# CC13x0 register map
File version: 2.0
CPU: CM3 r2p1, little endian, no MPU, no FPU, 0x3 interrupt priority bits, 0x0 interrupts
Registers are 32-bit, read-write, reset 0x0 unless marked. A register's access mark holds for its fields unless they carry their own. Offsets are from the block's base; [hi:lo] are bit positions; {n}, {i} and the like mark numbered series.

## CCFG — Customer configuration area (CCFG)
Base 0x50003000
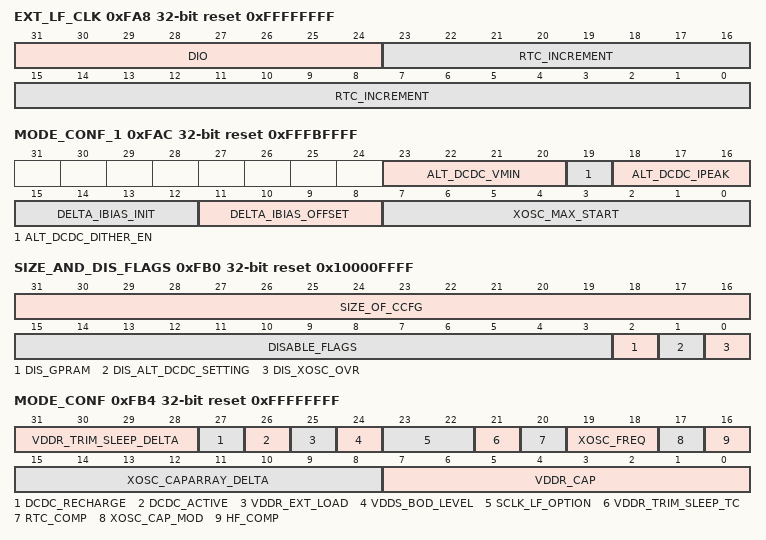
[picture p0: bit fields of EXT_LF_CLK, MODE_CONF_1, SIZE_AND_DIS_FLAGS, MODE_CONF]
0xFA8 EXT_LF_CLK ro reset 0xFFFFFFFF — Extern LF clock configuration
  [31:24] DIO, [23:0] RTC_INCREMENT
0xFAC MODE_CONF_1 ro reset 0xFFFBFFFF — Mode Configuration 1
  [23:20] ALT_DCDC_VMIN, [19] ALT_DCDC_DITHER_EN, [18:16] ALT_DCDC_IPEAK, [15:12] DELTA_IBIAS_INIT, [11:8] DELTA_IBIAS_OFFSET, [7:0] XOSC_MAX_START
0xFB0 SIZE_AND_DIS_FLAGS ro reset 0x10000FFFF — CCFG Size and Disable Flags
  [31:16] SIZE_OF_CCFG, [15:3] DISABLE_FLAGS, [2] DIS_GPRAM, [1] DIS_ALT_DCDC_SETTING, [0] DIS_XOSC_OVR
0xFB4 MODE_CONF ro reset 0xFFFFFFFF — Mode Configuration 0
  [31:28] VDDR_TRIM_SLEEP_DELTA, [27] DCDC_RECHARGE, [26] DCDC_ACTIVE, [25] VDDR_EXT_LOAD, [24] VDDS_BOD_LEVEL, [23:22] SCLK_LF_OPTION, [21] VDDR_TRIM_SLEEP_TC, [20] RTC_COMP, [19:18] XOSC_FREQ, [17] XOSC_CAP_MOD, [16] HF_COMP, [15:8] XOSC_CAPARRAY_DELTA, [7:0] VDDR_CAP
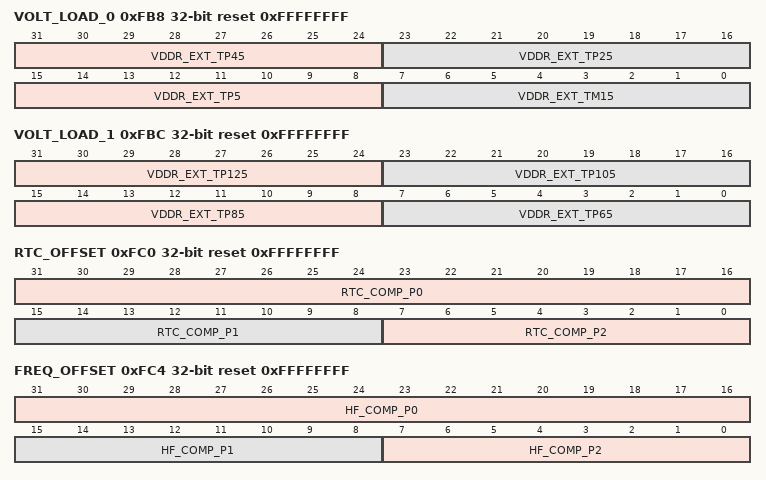
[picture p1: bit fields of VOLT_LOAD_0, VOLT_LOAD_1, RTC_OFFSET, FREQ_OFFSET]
0xFB8 VOLT_LOAD_0 ro reset 0xFFFFFFFF — Voltage Load 0 Enabled by MODE_CONF.VDDR_EXT_LOAD.
  [31:24] VDDR_EXT_TP45, [23:16] VDDR_EXT_TP25, [15:8] VDDR_EXT_TP5, [7:0] VDDR_EXT_TM15
0xFBC VOLT_LOAD_1 ro reset 0xFFFFFFFF — Voltage Load 1 Enabled by MODE_CONF.VDDR_EXT_LOAD.
  [31:24] VDDR_EXT_TP125, [23:16] VDDR_EXT_TP105, [15:8] VDDR_EXT_TP85, [7:0] VDDR_EXT_TP65
0xFC0 RTC_OFFSET ro reset 0xFFFFFFFF — Real Time Clock Offset Enabled by MODE_CONF.RTC_COMP.
  [31:16] RTC_COMP_P0, [15:8] RTC_COMP_P1, [7:0] RTC_COMP_P2
0xFC4 FREQ_OFFSET ro reset 0xFFFFFFFF — Frequency Offset
  [31:16] HF_COMP_P0, [15:8] HF_COMP_P1, [7:0] HF_COMP_P2
0xFC8 IEEE_MAC_0 ro reset 0xFFFFFFFF — IEEE MAC Address 0
  [31:0] ADDR
0xFCC IEEE_MAC_1 ro reset 0xFFFFFFFF — IEEE MAC Address 1
  [31:0] ADDR
0xFD0 IEEE_BLE_0 ro reset 0xFFFFFFFF — IEEE BLE Address 0
  [31:0] ADDR
0xFD4 IEEE_BLE_1 ro reset 0xFFFFFFFF — IEEE BLE Address 1
  [31:0] ADDR
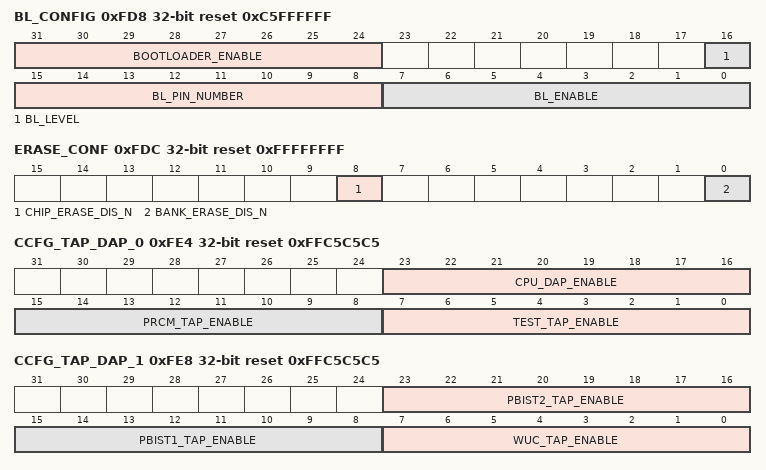
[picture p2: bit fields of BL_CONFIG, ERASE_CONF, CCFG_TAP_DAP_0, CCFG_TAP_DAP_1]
0xFD8 BL_CONFIG ro reset 0xC5FFFFFF — Bootloader Configuration Configures the functionality of the ROM boot loader. If both the boot loader is enabled by the BOOTLOADER_ENABLE field and the boot loader backdoor is enabled by the BL_ENABLE field it is possible to force entry of the ROM boot loader even if a valid image is present in flash.
  [31:24] BOOTLOADER_ENABLE, [16] BL_LEVEL, [15:8] BL_PIN_NUMBER, [7:0] BL_ENABLE
0xFDC ERASE_CONF ro reset 0xFFFFFFFF — Erase Configuration
  [8] CHIP_ERASE_DIS_N, [0] BANK_ERASE_DIS_N
0xFE0 CCFG_TI_OPTIONS ro reset 0xFFFFFFC5 — TI Options
  [7:0] TI_FA_ENABLE
0xFE4 CCFG_TAP_DAP_0 ro reset 0xFFC5C5C5 — Test Access Points Enable 0
  [23:16] CPU_DAP_ENABLE, [15:8] PRCM_TAP_ENABLE, [7:0] TEST_TAP_ENABLE
0xFE8 CCFG_TAP_DAP_1 ro reset 0xFFC5C5C5 — Test Access Points Enable 1
  [23:16] PBIST2_TAP_ENABLE, [15:8] PBIST1_TAP_ENABLE, [7:0] WUC_TAP_ENABLE
0xFEC IMAGE_VALID_CONF ro reset 0xFFFFFFFF — Image Valid
  [31:0] IMAGE_VALID
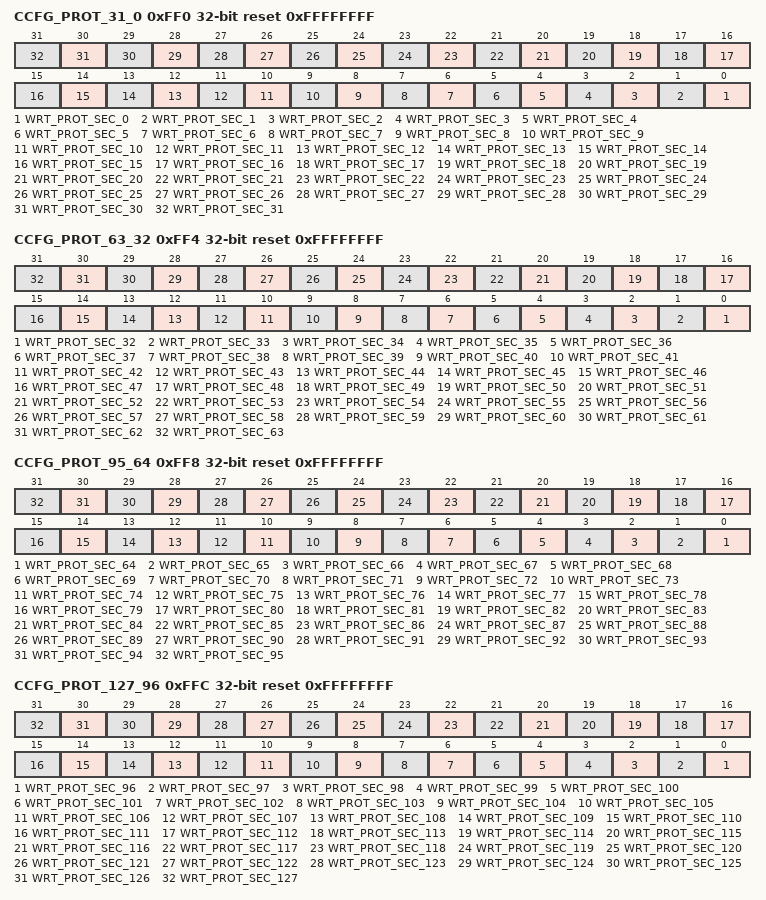
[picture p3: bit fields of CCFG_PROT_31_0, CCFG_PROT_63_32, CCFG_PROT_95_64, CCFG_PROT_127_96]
0xFF0 CCFG_PROT_31_0 ro reset 0xFFFFFFFF — Protect Sectors 0-31 Each bit write protects one 4KB flash sector from being both programmed and erased. Bit must be set to 0 in order to enable sector write protect.
  [n] WRT_PROT_SEC_{n} (n=0..31)
0xFF4 CCFG_PROT_63_32 ro reset 0xFFFFFFFF — Protect Sectors 32-63 Each bit write protects one 4KB flash sector from being both programmed and erased. Bit must be set to 0 in order to enable sector write protect. Not in use by CC26xx and CC13xx.
  [n-32] WRT_PROT_SEC_{n} (n=32..63)
0xFF8 CCFG_PROT_95_64 ro reset 0xFFFFFFFF — Protect Sectors 64-95 Each bit write protects one flash sector from being both programmed and erased. Bit must be set to 0 in order to enable sector write protect. Not in use by CC26xx and CC13xx.
  [n-64] WRT_PROT_SEC_{n} (n=64..95)
0xFFC CCFG_PROT_127_96 ro reset 0xFFFFFFFF — Protect Sectors 96-127 Each bit write protects one flash sector from being both programmed and erased. Bit must be set to 0 in order to enable sector write protect. Not in use by CC26xx and CC13xx.
  [n-96] WRT_PROT_SEC_{n} (n=96..127)
